VERSION ""

NS_ :

BS_:

BU_: XXX DSU HCU EPS IPAS CGW INTERCEPTOR EON BRAKE

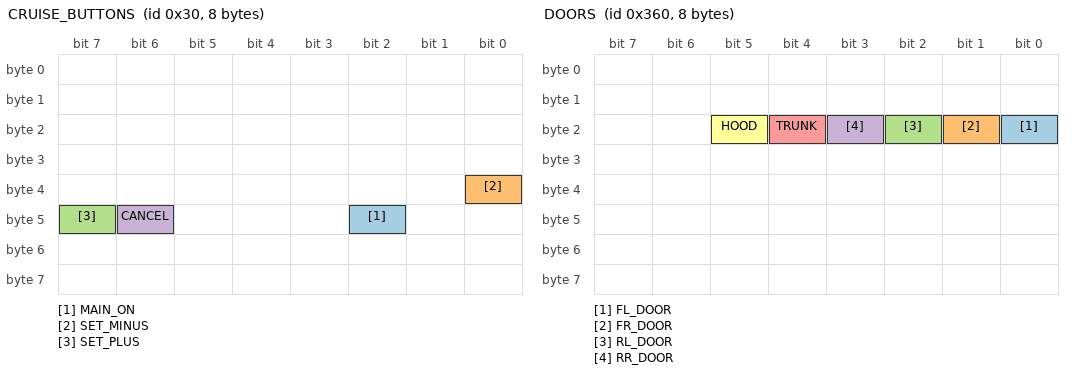
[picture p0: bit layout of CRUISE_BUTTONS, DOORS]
BO_ 48 CRUISE_BUTTONS: 8 XXX
 SG_ MAIN_ON : 42|1@0+ (1,0) [0|1] "" XXX
 SG_ SET_MINUS : 32|1@0+ (1,0) [0|1] "" XXX
 SG_ SET_PLUS : 47|1@0+ (1,0) [0|1] "" XXX
 SG_ CANCEL : 46|1@0+ (1,0) [0|1] "" XXX

BO_ 176 STEER_ANGLE_SENSOR: 8 XXX
 SG_ STEER_ANGLE : 46|15@0- (0.044444444,0) [0|65535] "" XXX

BO_ 320 STEER_TORQUE: 8 XXX
 SG_ DIRECTION : 21|1@0+ (1,0) [0|1] "" XXX
 SG_ DRIVER_TORQUE : 16|9@0+ (1,0) [0|16383] "" XXX

BO_ 128 GAS_BRAKE: 8 XXX
 SG_ BRAKE_PRESSED : 2|1@0+ (1,0) [0|511] "" XXX
 SG_ GAS_PEDAL : 1|10@0+ (1,0) [0|255] "" XXX

BO_ 864 DOORS: 8 XXX
 SG_ FL_DOOR : 16|1@0+ (1,0) [0|1] "" XXX
 SG_ FR_DOOR : 17|1@0+ (1,0) [0|1] "" XXX
 SG_ RL_DOOR : 18|1@0+ (1,0) [0|1] "" XXX
 SG_ RR_DOOR : 19|1@0+ (1,0) [0|1] "" XXX
 SG_ TRUNK : 20|1@0+ (1,0) [0|1] "" XXX
 SG_ HOOD : 21|1@0+ (1,0) [0|1] "" XXX

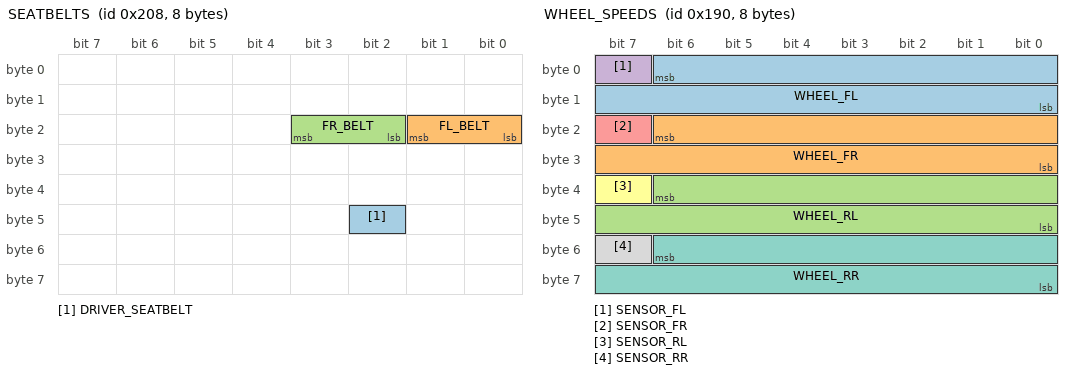
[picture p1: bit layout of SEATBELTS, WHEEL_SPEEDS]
BO_ 520 SEATBELTS: 8 XXX
 SG_ DRIVER_SEATBELT : 42|1@0+ (1,0) [0|1] "" XXX
 SG_ FL_BELT : 17|2@0+ (1,0) [0|3] "" XXX
 SG_ FR_BELT : 19|2@0+ (1,0) [0|3] "" XXX

BO_ 448 BRAKE_MODULE: 8 XXX
 SG_ BRAKE_PRESSURE : 51|12@0+ (1,0) [0|63] "" XXX

BO_ 400 WHEEL_SPEEDS: 8 XXX
 SG_ WHEEL_FL : 6|15@0+ (0.01,0) [0|65535] "" XXX
 SG_ WHEEL_FR : 22|15@0+ (0.01,0) [0|65535] "" XXX
 SG_ WHEEL_RL : 38|15@0+ (0.01,0) [0|65535] "" XXX
 SG_ SENSOR_FL : 7|1@0+ (1,0) [0|1] "" XXX
 SG_ SENSOR_FR : 23|1@0+ (1,0) [0|1] "" XXX
 SG_ SENSOR_RL : 39|1@0+ (1,0) [0|1] "" XXX
 SG_ WHEEL_RR : 54|15@0+ (0.01,0) [0|65535] "" XXX
 SG_ SENSOR_RR : 55|1@0+ (1,0) [0|1] "" XXX

BO_ 16 VSC: 8 XXX
 SG_ STEER_RATE : 35|12@0+ (0.05,0) [0|63] "" XXX

BO_ 224 GEAR_PACKET: 8 XXX
 SG_ GEAR : 37|3@0+ (1,0) [0|7] "" XXX

BO_ 608 SIGNAL_STALK: 8 XXX
 SG_ TURN_SIGNALS : 29|2@0+ (1,0) [0|3] "" XXX

CM_ SG_ 224 GEAR "0=P, 1=R, 2=N, 3=D, 4= S";
VAL_ 224 GEAR 2 "N" 1 "R" 3 "D" 4 "S" ;
